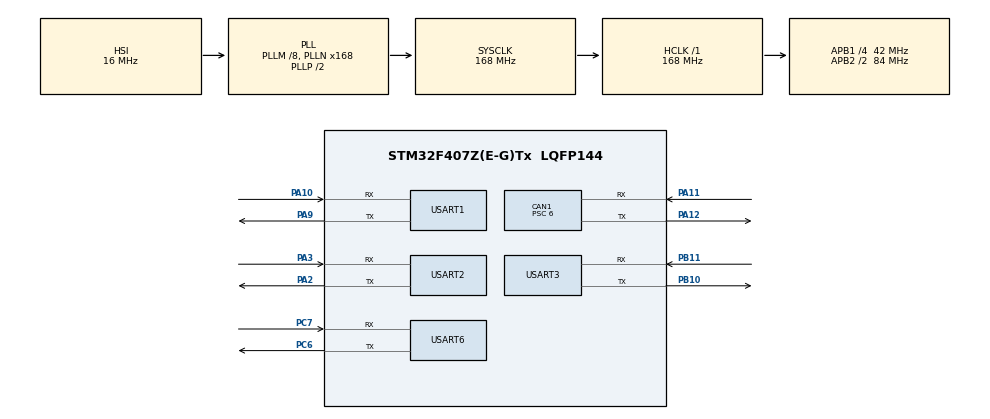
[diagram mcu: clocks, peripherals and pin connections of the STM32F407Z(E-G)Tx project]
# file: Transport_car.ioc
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CAN1.BS1=CAN_BS1_10TQ
CAN1.BS2=CAN_BS2_3TQ
CAN1.CalculateBaudRate=500000
CAN1.CalculateTimeBit=2000
CAN1.CalculateTimeQuantum=142.85714285714286
CAN1.Prescaler=6
Dma.Request0=USART1_RX
Dma.Request1=USART1_TX
Dma.Request2=USART2_RX
Dma.Request3=USART2_TX
Dma.Request4=USART3_RX
Dma.Request5=USART3_TX
Dma.USART1_RX.0.Direction=DMA_PERIPH_TO_MEMORY
Dma.USART1_RX.0.FIFOMode=DMA_FIFOMODE_DISABLE
Dma.USART1_RX.0.Instance=DMA2_Stream2
Dma.USART1_RX.0.MemDataAlignment=DMA_MDATAALIGN_BYTE
Dma.USART1_RX.0.MemInc=DMA_MINC_ENABLE
Dma.USART1_RX.0.Mode=DMA_NORMAL
Dma.USART1_RX.0.PeriphDataAlignment=DMA_PDATAALIGN_BYTE
Dma.USART1_RX.0.PeriphInc=DMA_PINC_DISABLE
Dma.USART1_RX.0.Priority=DMA_PRIORITY_LOW
Dma.USART1_TX.1.Direction=DMA_MEMORY_TO_PERIPH
Dma.USART1_TX.1.FIFOMode=DMA_FIFOMODE_DISABLE
Dma.USART1_TX.1.Instance=DMA2_Stream7
Dma.USART1_TX.1.MemDataAlignment=DMA_MDATAALIGN_BYTE
Dma.USART1_TX.1.MemInc=DMA_MINC_ENABLE
Dma.USART1_TX.1.Mode=DMA_NORMAL
Dma.USART1_TX.1.PeriphDataAlignment=DMA_PDATAALIGN_BYTE
Dma.USART1_TX.1.PeriphInc=DMA_PINC_DISABLE
Dma.USART1_TX.1.Priority=DMA_PRIORITY_MEDIUM
Dma.USART2_RX.2.Direction=DMA_PERIPH_TO_MEMORY
Dma.USART2_RX.2.FIFOMode=DMA_FIFOMODE_DISABLE
Dma.USART2_RX.2.Instance=DMA1_Stream5
Dma.USART2_RX.2.MemDataAlignment=DMA_MDATAALIGN_BYTE
Dma.USART2_RX.2.MemInc=DMA_MINC_ENABLE
Dma.USART2_RX.2.Mode=DMA_NORMAL
Dma.USART2_RX.2.PeriphDataAlignment=DMA_PDATAALIGN_BYTE
Dma.USART2_RX.2.PeriphInc=DMA_PINC_DISABLE
Dma.USART2_RX.2.Priority=DMA_PRIORITY_LOW
Dma.USART2_TX.3.Direction=DMA_MEMORY_TO_PERIPH
Dma.USART2_TX.3.FIFOMode=DMA_FIFOMODE_DISABLE
Dma.USART2_TX.3.Instance=DMA1_Stream6
Dma.USART2_TX.3.MemDataAlignment=DMA_MDATAALIGN_BYTE
Dma.USART2_TX.3.MemInc=DMA_MINC_ENABLE
Dma.USART2_TX.3.Mode=DMA_NORMAL
Dma.USART2_TX.3.PeriphDataAlignment=DMA_PDATAALIGN_BYTE
Dma.USART2_TX.3.PeriphInc=DMA_PINC_DISABLE
Dma.USART2_TX.3.Priority=DMA_PRIORITY_LOW
Dma.USART3_RX.4.Direction=DMA_PERIPH_TO_MEMORY
Dma.USART3_RX.4.FIFOMode=DMA_FIFOMODE_DISABLE
Dma.USART3_RX.4.Instance=DMA1_Stream1
Dma.USART3_RX.4.MemDataAlignment=DMA_MDATAALIGN_BYTE
Dma.USART3_RX.4.MemInc=DMA_MINC_ENABLE
Dma.USART3_RX.4.Mode=DMA_NORMAL
Dma.USART3_RX.4.PeriphDataAlignment=DMA_PDATAALIGN_BYTE
Dma.USART3_RX.4.PeriphInc=DMA_PINC_DISABLE
Dma.USART3_RX.4.Priority=DMA_PRIORITY_HIGH
Dma.USART3_TX.5.Direction=DMA_MEMORY_TO_PERIPH
Dma.USART3_TX.5.FIFOMode=DMA_FIFOMODE_DISABLE
Dma.USART3_TX.5.Instance=DMA1_Stream3
Dma.USART3_TX.5.MemDataAlignment=DMA_MDATAALIGN_BYTE
Dma.USART3_TX.5.MemInc=DMA_MINC_ENABLE
Dma.USART3_TX.5.Mode=DMA_NORMAL
Dma.USART3_TX.5.PeriphDataAlignment=DMA_PDATAALIGN_BYTE
Dma.USART3_TX.5.PeriphInc=DMA_PINC_DISABLE
Dma.USART3_TX.5.Priority=DMA_PRIORITY_LOW
FREERTOS.Tasks01=defaultTask,24,128,StartDefaultTask,Default,NULL,Dynamic,NULL,NULL;MotorTask,24,512,OS_MotorCallback,As weak,NULL,Dynamic,NULL,NULL;ChassisTask,24,512,OS_ChassisCallback,As weak,NULL,Dynamic,NULL,NULL;GimbalTask,24,256,OS_GimbalCallback,As weak,NULL,Dynamic,NULL,NULL;VisionTask,24,256,OS_VisionCallback,As weak,NULL,Dynamic,NULL,NULL;NavigationTask,24,512,OS_NavigationCallback,As weak,NULL,Dynamic,NULL,NULL;IMUTask,24,512,OS_IMUCallback,As weak,NULL,Dynamic,NULL,NULL
Mcu.Family=STM32F4
Mcu.Name=STM32F407Z(E-G)Tx
Mcu.Package=LQFP144
NVIC.CAN1_RX0_IRQn=true\:5\:0\:false\:false\:true\:true\:true\:true\:true
NVIC.CAN1_RX1_IRQn=true\:5\:0\:false\:false\:true\:true\:true\:true\:true
NVIC.DMA1_Stream1_IRQn=true\:5\:0\:false\:false\:true\:true\:false\:true\:true
NVIC.DMA1_Stream3_IRQn=true\:5\:0\:false\:false\:true\:true\:false\:true\:true
NVIC.DMA1_Stream5_IRQn=true\:5\:0\:false\:false\:true\:true\:false\:true\:true
NVIC.DMA1_Stream6_IRQn=true\:5\:0\:false\:false\:true\:true\:false\:true\:true
NVIC.DMA2_Stream2_IRQn=true\:5\:0\:false\:false\:true\:true\:false\:true\:true
NVIC.DMA2_Stream7_IRQn=true\:5\:0\:false\:false\:true\:true\:false\:true\:true
NVIC.PriorityGroup=NVIC_PRIORITYGROUP_4
NVIC.TIM2_IRQn=true\:15\:0\:false\:false\:true\:false\:false\:true\:true
NVIC.TimeBase=TIM2_IRQn
NVIC.TimeBaseIP=TIM2
NVIC.USART1_IRQn=true\:5\:0\:false\:false\:true\:true\:true\:true\:true
NVIC.USART2_IRQn=true\:5\:0\:false\:false\:true\:true\:true\:true\:true
NVIC.USART3_IRQn=true\:5\:0\:false\:false\:true\:true\:true\:true\:true
NVIC.USART6_IRQn=true\:5\:0\:false\:false\:true\:true\:true\:true\:true
PA10.GPIO_PuPd=GPIO_PULLUP
PA10.Mode=Asynchronous
PA10.Signal=USART1_RX
PA11.Mode=CAN_Activate
PA11.Signal=CAN1_RX
PA12.Mode=CAN_Activate
PA12.Signal=CAN1_TX
PA13.Mode=Serial_Wire
PA13.Signal=SYS_JTMS-SWDIO
PA14.Mode=Serial_Wire
PA14.Signal=SYS_JTCK-SWCLK
PA2.Mode=Asynchronous
PA2.Signal=USART2_TX
PA3.GPIO_PuPd=GPIO_PULLUP
PA3.Mode=Asynchronous
PA3.Signal=USART2_RX
PA9.GPIO_PuPd=GPIO_NOPULL
PA9.Mode=Asynchronous
PA9.Signal=USART1_TX
PB10.Mode=Asynchronous
PB10.Signal=USART3_TX
PB11.GPIO_PuPd=GPIO_PULLUP
PB11.Mode=Asynchronous
PB11.Signal=USART3_RX
PC6.Mode=Asynchronous
PC6.Signal=USART6_TX
PC7.GPIO_PuPd=GPIO_PULLUP
PC7.Mode=Asynchronous
PC7.Signal=USART6_RX
PH0-OSC_IN.Mode=HSE-External-Oscillator
PH0-OSC_IN.Signal=RCC_OSC_IN
PH1-OSC_OUT.Mode=HSE-External-Oscillator
PH1-OSC_OUT.Signal=RCC_OSC_OUT
ProjectManager.HeapSize=0x200
ProjectManager.StackSize=0x400
ProjectManager.TargetToolchain=CMake
RCC.48MHZClocksFreq_Value=84000000
RCC.AHBFreq_Value=168000000
RCC.APB1CLKDivider=RCC_HCLK_DIV4
RCC.APB1Freq_Value=42000000
RCC.APB1TimFreq_Value=84000000
RCC.APB2CLKDivider=RCC_HCLK_DIV2
RCC.APB2Freq_Value=84000000
RCC.APB2TimFreq_Value=168000000
RCC.CortexFreq_Value=168000000
RCC.HCLKFreq_Value=168000000
RCC.HSE_VALUE=24000000
RCC.HSI_VALUE=16000000
RCC.LSE_VALUE=32768
RCC.PLLM=8
RCC.PLLN=168
RCC.SYSCLKFreq_VALUE=168000000
RCC.SYSCLKSource=RCC_SYSCLKSOURCE_PLLCLK
RCC.VCOOutputFreq_Value=336000000
USART1.VirtualMode=VM_ASYNC
USART2.VirtualMode=VM_ASYNC
USART3.VirtualMode=VM_ASYNC
USART6.VirtualMode=VM_ASYNC
VP_FREERTOS_VS_CMSIS_V2.Mode=CMSIS_V2
VP_SYS_VS_tim2.Mode=TIM2
board=custom

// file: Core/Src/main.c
/* USER CODE BEGIN Header */
/**
  ******************************************************************************
  * @file           : main.c
  * @brief          : Main program body
  ******************************************************************************
  * @attention
  *
  * Copyright (c) 2026 STMicroelectronics.
  * All rights reserved.
  *
  * This software is licensed under terms that can be found in the LICENSE file
  * in the root directory of this software component.
  * If no LICENSE file comes with this software, it is provided AS-IS.
  *
  ******************************************************************************
  */
/* USER CODE END Header */
#include "main.h"
#include "cmsis_os.h"
#include "can.h"
#include "dma.h"
#include "usart.h"
#include "gpio.h"

/* USER CODE BEGIN Includes */

#include "bsp_usart.h"
#include "Chassis.h"
#include "Gimbal.h"
#include "Vision.h"

/* USER CODE END Includes */

void SystemClock_Config(void);
void MX_FREERTOS_Init(void);

int main(void)
{

  /* MCU Configuration--------------------------------------------------------*/

  /* Reset of all peripherals, Initializes the Flash interface and the Systick. */
  HAL_Init();

  /* Configure the system clock */
  SystemClock_Config();

  /* Initialize all configured peripherals */
  MX_GPIO_Init();
  MX_DMA_Init();
  MX_USART1_UART_Init();
  MX_CAN1_Init();
  MX_USART2_UART_Init();
  MX_USART3_UART_Init();
  MX_USART6_UART_Init();
  /* USER CODE BEGIN 2 */

  Chassis_Init();
  Gimbal_Init();
  Vision_Init();
  // Bsp_Usart_Init();

  /* USER CODE END 2 */

  /* Init scheduler */
  osKernelInitialize();  /* Call init function for freertos objects (in cmsis_os2.c) */
  MX_FREERTOS_Init();

  /* Start scheduler */
  osKernelStart();

  /* We should never get here as control is now taken by the scheduler */

  /* Infinite loop */
  while (1)
  {

  }
}

void SystemClock_Config(void)
{
  RCC_OscInitTypeDef RCC_OscInitStruct = {0};
  RCC_ClkInitTypeDef RCC_ClkInitStruct = {0};

  /** Configure the main internal regulator output voltage
  */
  __HAL_RCC_PWR_CLK_ENABLE();
  __HAL_PWR_VOLTAGESCALING_CONFIG(PWR_REGULATOR_VOLTAGE_SCALE1);

  /** Initializes the RCC Oscillators according to the specified parameters
  * in the RCC_OscInitTypeDef structure.
  */
  RCC_OscInitStruct.OscillatorType = RCC_OSCILLATORTYPE_HSI;
  RCC_OscInitStruct.HSIState = RCC_HSI_ON;
  RCC_OscInitStruct.HSICalibrationValue = RCC_HSICALIBRATION_DEFAULT;
  RCC_OscInitStruct.PLL.PLLState = RCC_PLL_ON;
  RCC_OscInitStruct.PLL.PLLSource = RCC_PLLSOURCE_HSI;
  RCC_OscInitStruct.PLL.PLLM = 8;
  RCC_OscInitStruct.PLL.PLLN = 168;
  RCC_OscInitStruct.PLL.PLLP = RCC_PLLP_DIV2;
  RCC_OscInitStruct.PLL.PLLQ = 4;
  if (HAL_RCC_OscConfig(&RCC_OscInitStruct) != HAL_OK)
  {
    Error_Handler();
  }

  /** Initializes the CPU, AHB and APB buses clocks
  */
  RCC_ClkInitStruct.ClockType = RCC_CLOCKTYPE_HCLK|RCC_CLOCKTYPE_SYSCLK
                              |RCC_CLOCKTYPE_PCLK1|RCC_CLOCKTYPE_PCLK2;
  RCC_ClkInitStruct.SYSCLKSource = RCC_SYSCLKSOURCE_PLLCLK;
  RCC_ClkInitStruct.AHBCLKDivider = RCC_SYSCLK_DIV1;
  RCC_ClkInitStruct.APB1CLKDivider = RCC_HCLK_DIV4;
  RCC_ClkInitStruct.APB2CLKDivider = RCC_HCLK_DIV2;

  if (HAL_RCC_ClockConfig(&RCC_ClkInitStruct, FLASH_LATENCY_5) != HAL_OK)
  {
    Error_Handler();
  }
}

void HAL_TIM_PeriodElapsedCallback(TIM_HandleTypeDef *htim)
{
  if (htim->Instance == TIM2)
  {
    HAL_IncTick();
  }
}

void Error_Handler(void)
{
  __disable_irq();
  while (1)
  {
  }
}

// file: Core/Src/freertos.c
/* USER CODE BEGIN Header */
/**
  ******************************************************************************
  * File Name          : freertos.c
  * Description        : Code for freertos applications
  ******************************************************************************
  * @attention
  *
  * Copyright (c) 2026 STMicroelectronics.
  * All rights reserved.
  *
  * This software is licensed under terms that can be found in the LICENSE file
  * in the root directory of this software component.
  * If no LICENSE file comes with this software, it is provided AS-IS.
  *
  ******************************************************************************
  */
/* USER CODE END Header */

#include "FreeRTOS.h"
#include "task.h"
#include "main.h"
#include "cmsis_os.h"

/* Definitions for defaultTask */
osThreadId_t defaultTaskHandle;
const osThreadAttr_t defaultTask_attributes = {
  .name = "defaultTask",
  .stack_size = 128 * 4,
  .priority = (osPriority_t) osPriorityNormal,
};
/* Definitions for MotorTask */
osThreadId_t MotorTaskHandle;
const osThreadAttr_t MotorTask_attributes = {
  .name = "MotorTask",
  .stack_size = 512 * 4,
  .priority = (osPriority_t) osPriorityNormal,
};
/* Definitions for ChassisTask */
osThreadId_t ChassisTaskHandle;
const osThreadAttr_t ChassisTask_attributes = {
  .name = "ChassisTask",
  .stack_size = 512 * 4,
  .priority = (osPriority_t) osPriorityNormal,
};
/* Definitions for GimbalTask */
osThreadId_t GimbalTaskHandle;
const osThreadAttr_t GimbalTask_attributes = {
  .name = "GimbalTask",
  .stack_size = 256 * 4,
  .priority = (osPriority_t) osPriorityNormal,
};
/* Definitions for VisionTask */
osThreadId_t VisionTaskHandle;
const osThreadAttr_t VisionTask_attributes = {
  .name = "VisionTask",
  .stack_size = 256 * 4,
  .priority = (osPriority_t) osPriorityNormal,
};
/* Definitions for NavigationTask */
osThreadId_t NavigationTaskHandle;
const osThreadAttr_t NavigationTask_attributes = {
  .name = "NavigationTask",
  .stack_size = 512 * 4,
  .priority = (osPriority_t) osPriorityNormal,
};
/* Definitions for IMUTask */
osThreadId_t IMUTaskHandle;
const osThreadAttr_t IMUTask_attributes = {
  .name = "IMUTask",
  .stack_size = 512 * 4,
  .priority = (osPriority_t) osPriorityNormal,
};

void StartDefaultTask(void *argument);
void OS_MotorCallback(void *argument);
void OS_ChassisCallback(void *argument);
void OS_GimbalCallback(void *argument);
void OS_VisionCallback(void *argument);
void OS_NavigationCallback(void *argument);
void OS_IMUCallback(void *argument);

void MX_FREERTOS_Init(void); /* (MISRA C 2004 rule 8.1) */

void MX_FREERTOS_Init(void) {

  /* Create the thread(s) */
  /* creation of defaultTask */
  defaultTaskHandle = osThreadNew(StartDefaultTask, NULL, &defaultTask_attributes);

  /* creation of MotorTask */
  MotorTaskHandle = osThreadNew(OS_MotorCallback, NULL, &MotorTask_attributes);

  /* creation of ChassisTask */
  ChassisTaskHandle = osThreadNew(OS_ChassisCallback, NULL, &ChassisTask_attributes);

  /* creation of GimbalTask */
  GimbalTaskHandle = osThreadNew(OS_GimbalCallback, NULL, &GimbalTask_attributes);

  /* creation of VisionTask */
  VisionTaskHandle = osThreadNew(OS_VisionCallback, NULL, &VisionTask_attributes);

  /* creation of NavigationTask */
  NavigationTaskHandle = osThreadNew(OS_NavigationCallback, NULL, &NavigationTask_attributes);

  /* creation of IMUTask */
  IMUTaskHandle = osThreadNew(OS_IMUCallback, NULL, &IMUTask_attributes);

}

void StartDefaultTask(void *argument)
{
  for(;;)
  {
    osDelay(1);
  }
}

__weak void OS_MotorCallback(void *argument)
{
  for(;;)
  {
    osDelay(1);
  }
}

__weak void OS_ChassisCallback(void *argument)
{
  for(;;)
  {
    osDelay(1);
  }
}

__weak void OS_GimbalCallback(void *argument)
{
  for(;;)
  {
    osDelay(1);
  }
}

__weak void OS_VisionCallback(void *argument)
{
  for(;;)
  {
    osDelay(1);
  }
}

__weak void OS_NavigationCallback(void *argument)
{
  for(;;)
  {
    osDelay(1);
  }
}

__weak void OS_IMUCallback(void *argument)
{
  for(;;)
  {
    osDelay(1);
  }
}
